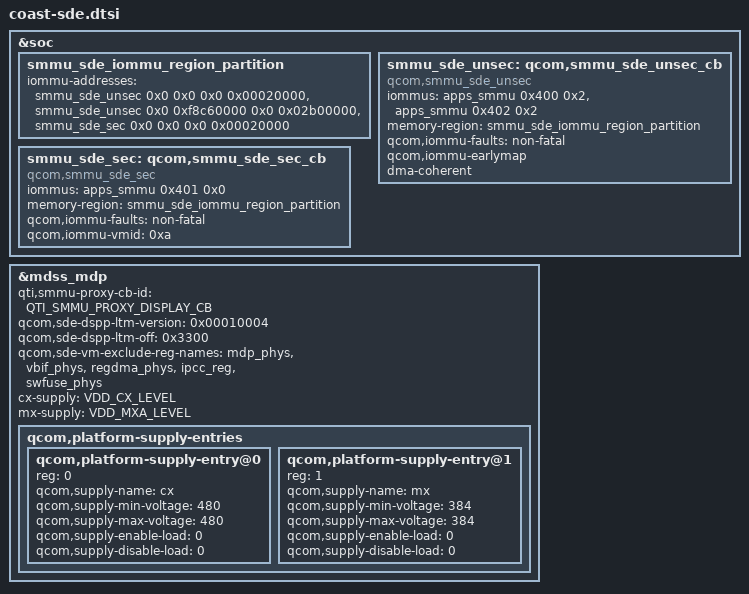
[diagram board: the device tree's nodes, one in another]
// SPDX-License-Identifier: BSD-3-Clause
/*
 * Copyright (c) Qualcomm Technologies, Inc. and/or its subsidiaries.
 */

#include <dt-bindings/clock/qcom,rpmh.h>
#include <dt-bindings/arm/msm/qti-smmu-proxy-dt-ids.h>
#include <dt-bindings/clock/qcom,coast-tcsrcc.h>
#include <dt-bindings/clock/qcom,coast-gcc.h>
#include "coast-sde-common.dtsi"

&soc {
	smmu_sde_iommu_region_partition: smmu_sde_iommu_region_partition {
		iommu-addresses = <&smmu_sde_unsec 0x0 0x0 0x0 0x00020000>,
				<&smmu_sde_unsec 0x0 0xf8c60000 0x0 0x02b00000>,
				<&smmu_sde_sec 0x0 0x0 0x0 0x00020000>;
	};

	smmu_sde_unsec: qcom,smmu_sde_unsec_cb {
		compatible = "qcom,smmu_sde_unsec";
		iommus = <&apps_smmu 0x400 0x2>, <&apps_smmu 0x402 0x2>;
		memory-region = <&smmu_sde_iommu_region_partition>;
		qcom,iommu-faults = "non-fatal";
		qcom,iommu-earlymap; /* for cont-splash */
		dma-coherent;
	};

	smmu_sde_sec: qcom,smmu_sde_sec_cb {
		compatible = "qcom,smmu_sde_sec";
		iommus = <&apps_smmu 0x401 0x0>;
		memory-region = <&smmu_sde_iommu_region_partition>;
		qcom,iommu-faults = "non-fatal";
		qcom,iommu-vmid = <0xa>;
	};

};

&mdss_mdp {
	qti,smmu-proxy-cb-id = <QTI_SMMU_PROXY_DISPLAY_CB>;
	qcom,sde-dspp-ltm-version = <0x00010004>;
	/* offsets are based off dspp 0, 1, 2, and 3 */
	qcom,sde-dspp-ltm-off = <0x3300>;

	qcom,sde-vm-exclude-reg-names = "mdp_phys", "vbif_phys",
					"regdma_phys", "ipcc_reg",
					"swfuse_phys";
	cx-supply = <&VDD_CX_LEVEL>;
	mx-supply = <&VDD_MXA_LEVEL>;

	/* Pre mdss_core vregs */
	qcom,platform-supply-entries {
		#address-cells = <1>;
		#size-cells = <0>;

		qcom,platform-supply-entry@0 {
			reg = <0>;
			qcom,supply-name = "cx";
			qcom,supply-min-voltage = <480>;
			qcom,supply-max-voltage = <480>;
			qcom,supply-enable-load = <0>;
			qcom,supply-disable-load = <0>;
		};

		qcom,platform-supply-entry@1 {
			reg = <1>;
			qcom,supply-name = "mx";
			qcom,supply-min-voltage = <384>;
			qcom,supply-max-voltage = <384>;
			qcom,supply-enable-load = <0>;
			qcom,supply-disable-load = <0>;
		};
	};
};
